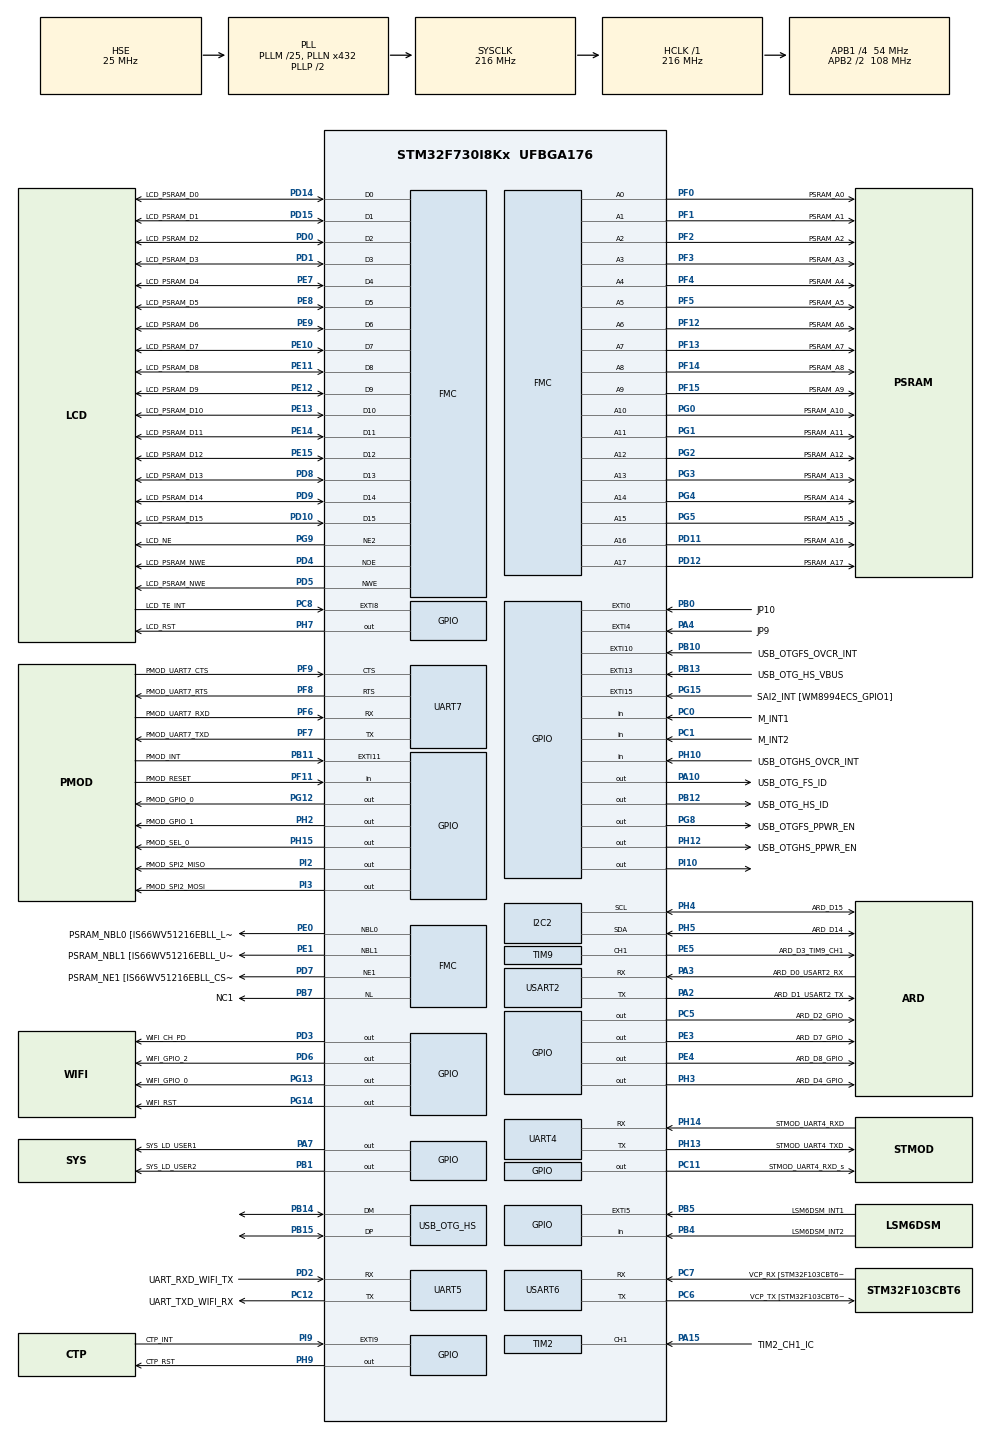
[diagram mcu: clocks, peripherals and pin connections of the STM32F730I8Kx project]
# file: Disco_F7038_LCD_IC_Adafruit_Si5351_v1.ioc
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FMC.WriteOperation1=FMC_WRITE_OPERATION_ENABLE
I2C2.Timing=0x20404768
Mcu.Family=STM32F7
Mcu.Name=STM32F730I8Kx
Mcu.Package=UFBGA176
NVIC.PriorityGroup=NVIC_PRIORITYGROUP_4
NVIC.TIM2_IRQn=true\:0\:0\:false\:false\:true\:true\:true
PA0-WKUP.GPIO_Label=SYS_B_User
PA0-WKUP.Mode=SYS_WakeUp0
PA0-WKUP.Signal=SYS_WKUP1
PA1.GPIO_Label=TIM2_PWM_CH2
PA1.Signal=S_TIM2_CH2
PA10.GPIO_Label=USB_OTG_FS_ID
PA10.Signal=GPIO_Output
PA11.Signal=USB_OTG_FS_DM
PA12.Signal=USB_OTG_FS_DP
PA13.Mode=Trace_Asynchronous_SW
PA13.Signal=SYS_JTMS-SWDIO
PA14.Mode=Trace_Asynchronous_SW
PA14.Signal=SYS_JTCK-SWCLK
PA15.GPIO_Label=TIM2_CH1_IC
PA15.Signal=S_TIM2_CH1_ETR
PA2.GPIO_Label=ARD_D1_USART2_TX
PA2.Mode=Asynchronous
PA2.Signal=USART2_TX
PA3.GPIO_Label=ARD_D0_USART2_RX
PA3.Mode=Asynchronous
PA3.Signal=USART2_RX
PA4.GPIO_Label=JP9
PA4.Signal=GPXTI4
PA5.GPIO_Label=ARD_D13_SPI1_SCK
PA5.Signal=SPI1_SCK
PA6.GPIO_Label=ARD_A0
PA6.Signal=ADCx_IN6
PA7.GPIO_Label=SYS_LD_USER1
PA7.Signal=GPIO_Output
PA8.GPIO_Label=CTP_SCL
PA8.Signal=I2C3_SCL
PA9.Signal=USB_OTG_FS_VBUS
PB0.GPIO_Label=JP10
PB0.Signal=GPXTI0
PB1.GPIO_Label=SYS_LD_USER2
PB1.Signal=GPIO_Output
PB10.GPIO_Label=USB_OTGFS_OVCR_INT
PB10.Signal=GPXTI10
PB11.GPIO_Label=PMOD_INT
PB11.Signal=GPXTI11
PB12.GPIO_Label=USB_OTG_HS_ID
PB12.Signal=GPIO_Output
PB13.GPIO_Label=USB_OTG_HS_VBUS
PB13.Signal=GPXTI13
PB14.Mode=Internal_Phy_Host
PB14.Signal=USB_OTG_HS_DM
PB15.Mode=Internal_Phy_Host
PB15.Signal=USB_OTG_HS_DP
PB2.GPIO_Label=QSPI_CLK [MX25L51245G_SCLK]
PB2.Signal=QUADSPI_CLK
PB3.GPIO_Label=SYS_STLINK_JTDO_SWO
PB3.Mode=Trace_Asynchronous_SW
PB3.Signal=SYS_JTDO-SWO
PB4.GPIO_Label=LSM6DSM_INT2
PB4.Signal=GPIO_Input
PB5.GPIO_Label=LSM6DSM_INT1
PB5.Signal=GPXTI5
PB6.GPIO_Label=QSPI_NCS [MX25L51245G_CS]
PB6.Signal=QUADSPI_BK1_NCS
PB7.GPIO_Label=NC1
PB7.Signal=FMC_NL
PC0.GPIO_Label=M_INT1
PC0.Signal=GPIO_Input
PC1.GPIO_Label=M_INT2
PC1.Signal=GPIO_Input
PC10.GPIO_Label=QSPI_D1 [MX25L51245G_SIO1]
PC10.Signal=QUADSPI_BK1_IO1
PC11.GPIO_Label=STMOD_UART4_RXD_s
PC11.Signal=GPIO_Output
PC12.GPIO_Label=UART_TXD_WIFI_RX
PC12.Mode=Asynchronous
PC12.Signal=UART5_TX
PC14-OSC32_IN.Mode=LSE-External-Oscillator
PC14-OSC32_IN.Signal=RCC_OSC32_IN
PC15-OSC32_OUT.Mode=LSE-External-Oscillator
PC15-OSC32_OUT.Signal=RCC_OSC32_OUT
PC2.GPIO_Label=STMOD_SPI2_MISOs
PC2.Signal=SPI2_MISO
PC3.GPIO_Label=STMOD+_SPI2_MOSIs
PC3.Signal=SPI2_MOSI
PC4.GPIO_Label=ARD_A2
PC4.Signal=ADCx_IN14
PC5.GPIO_Label=ARD_D2_GPIO
PC5.Signal=GPIO_Output
PC6.GPIO_Label=VCP_TX [STM32F103CBT6_PA3]
PC6.Mode=Asynchronous
PC6.Signal=USART6_TX
PC7.GPIO_Label=VCP_RX [STM32F103CBT6_PA2]
PC7.Mode=Asynchronous
PC7.Signal=USART6_RX
PC8.GPIO_Label=LCD_TE_INT
PC8.Signal=GPXTI8
PC9.GPIO_Label=QSPI_D0 [MX25L51245G_SIO0]
PC9.Signal=QUADSPI_BK1_IO0
PD0.GPIO_Label=LCD_PSRAM_D2
PD0.Signal=FMC_D2_DA2
PD1.GPIO_Label=LCD_PSRAM_D3
PD1.Signal=FMC_D3_DA3
PD10.GPIO_Label=LCD_PSRAM_D15
PD10.Signal=FMC_D15_DA15
PD11.GPIO_Label=PSRAM_A16
PD11.Signal=FMC_A16_CLE
PD12.GPIO_Label=PSRAM_A17
PD12.Signal=FMC_A17_ALE
PD13.GPIO_Label=QSPI_D3 [MX25L51245G_SIO3]
PD13.Signal=QUADSPI_BK1_IO3
PD14.GPIO_Label=LCD_PSRAM_D0
PD14.Signal=FMC_D0_DA0
PD15.GPIO_Label=LCD_PSRAM_D1
PD15.Signal=FMC_D1_DA1
PD2.GPIO_Label=UART_RXD_WIFI_TX
PD2.Mode=Asynchronous
PD2.Signal=UART5_RX
PD3.GPIO_Label=WIFI_CH_PD
PD3.Signal=GPIO_Output
PD4.GPIO_Label=LCD_PSRAM_NWE
PD4.Signal=FMC_NOE
PD5.GPIO_Label=LCD_PSRAM_NWE
PD5.Signal=FMC_NWE
PD6.GPIO_Label=WIFI_GPIO_2
PD6.Signal=GPIO_Output
PD7.GPIO_Label=PSRAM_NE1 [IS66WV51216EBLL_CS1]
PD7.Mode=NorPsramChipSelect1_1
PD7.Signal=FMC_NE1
PD8.GPIO_Label=LCD_PSRAM_D13
PD8.Signal=FMC_D13_DA13
PD9.GPIO_Label=LCD_PSRAM_D14
PD9.Signal=FMC_D14_DA14
PE0.GPIO_Label=PSRAM_NBL0 [IS66WV51216EBLL_LB]
PE0.Signal=FMC_NBL0
PE1.GPIO_Label=PSRAM_NBL1 [IS66WV51216EBLL_UB]
PE1.Signal=FMC_NBL1
PE10.GPIO_Label=LCD_PSRAM_D7
PE10.Signal=FMC_D7_DA7
PE11.GPIO_Label=LCD_PSRAM_D8
PE11.Signal=FMC_D8_DA8
PE12.GPIO_Label=LCD_PSRAM_D9
PE12.Signal=FMC_D9_DA9
PE13.GPIO_Label=LCD_PSRAM_D10
PE13.Signal=FMC_D10_DA10
PE14.GPIO_Label=LCD_PSRAM_D11
PE14.Signal=FMC_D11_DA11
PE15.GPIO_Label=LCD_PSRAM_D12
PE15.Signal=FMC_D12_DA12
PE2.GPIO_Label=QSPI_D2 [MX25L51245G_SIO2]
PE2.Signal=QUADSPI_BK1_IO2
PE3.GPIO_Label=ARD_D7_GPIO
PE3.Signal=GPIO_Output
PE4.GPIO_Label=ARD_D8_GPIO
PE4.Signal=GPIO_Output
PE5.GPIO_Label=ARD_D3_TIM9_CH1
PE5.Signal=S_TIM9_CH1
PE6.GPIO_Label=ARD_D6_TIM9_CH2
PE6.Signal=S_TIM9_CH2
PE7.GPIO_Label=LCD_PSRAM_D4
PE7.Signal=FMC_D4_DA4
PE8.GPIO_Label=LCD_PSRAM_D5
PE8.Signal=FMC_D5_DA5
PE9.GPIO_Label=LCD_PSRAM_D6
PE9.Signal=FMC_D6_DA6
PF0.GPIO_Label=PSRAM_A0
PF0.Signal=FMC_A0
PF1.GPIO_Label=PSRAM_A1
PF1.Signal=FMC_A1
PF10.GPIO_Label=ARD_A3_ADC3_IN8
PF10.Signal=ADC3_IN8
PF11.GPIO_Label=PMOD_RESET
PF11.Signal=GPIO_Input
PF12.GPIO_Label=PSRAM_A6
PF12.Signal=FMC_A6
PF13.GPIO_Label=PSRAM_A7
PF13.Signal=FMC_A7
PF14.GPIO_Label=PSRAM_A8
PF14.Signal=FMC_A8
PF15.GPIO_Label=PSRAM_A9
PF15.Signal=FMC_A9
PF2.GPIO_Label=PSRAM_A2
PF2.Signal=FMC_A2
PF3.GPIO_Label=PSRAM_A3
PF3.Signal=FMC_A3
PF4.GPIO_Label=PSRAM_A4
PF4.Signal=FMC_A4
PF5.GPIO_Label=PSRAM_A5
PF5.Signal=FMC_A5
PF6.GPIO_Label=PMOD_UART7_RXD
PF6.Mode=Asynchronous
PF6.Signal=UART7_RX
PF7.GPIO_Label=PMOD_UART7_TXD
PF7.Mode=Asynchronous
PF7.Signal=UART7_TX
PF8.GPIO_Label=PMOD_UART7_RTS
PF8.Mode=CTS_RTS
PF8.Signal=UART7_RTS
PF9.GPIO_Label=PMOD_UART7_CTS
PF9.Mode=CTS_RTS
PF9.Signal=UART7_CTS
PG0.GPIO_Label=PSRAM_A10
PG0.Signal=FMC_A10
PG1.GPIO_Label=PSRAM_A11
PG1.Signal=FMC_A11
PG10.GPIO_Label=SAI2_SD_B [SAI2_SD_B_ADCDAT1]
PG10.Signal=SAI2_SD_B
PG12.GPIO_Label=PMOD_GPIO_0
PG12.Signal=GPIO_Output
PG13.GPIO_Label=WIFI_GPIO_0
PG13.Signal=GPIO_Output
PG14.GPIO_Label=WIFI_RST
PG14.Signal=GPIO_Output
PG15.GPIO_Label=SAI2_INT [WM8994ECS_GPIO1]
PG15.Signal=GPXTI15
PG2.GPIO_Label=PSRAM_A12
PG2.Signal=FMC_A12
PG3.GPIO_Label=PSRAM_A13
PG3.Signal=FMC_A13
PG4.GPIO_Label=PSRAM_A14
PG4.Signal=FMC_A14_BA0
PG5.GPIO_Label=PSRAM_A15
PG5.Signal=FMC_A15_BA1
PG8.GPIO_Label=USB_OTGFS_PPWR_EN
PG8.Signal=GPIO_Output
PG9.GPIO_Label=LCD_NE
PG9.Mode=NorPsramChipSelect2_2
PG9.Signal=FMC_NE2
PH0-OSC_IN.Mode=HSE-External-Oscillator
PH0-OSC_IN.Signal=RCC_OSC_IN
PH1-OSC_OUT.Mode=HSE-External-Oscillator
PH1-OSC_OUT.Signal=RCC_OSC_OUT
PH10.GPIO_Label=USB_OTGHS_OVCR_INT
PH10.Signal=GPIO_Input
PH11.GPIO_Label=LCD_BL [STLD40DPUR_EN]
PH11.Signal=S_TIM5_CH2
PH12.GPIO_Label=USB_OTGHS_PPWR_EN
PH12.Signal=GPIO_Output
PH13.GPIO_Label=STMOD_UART4_TXD
PH13.Mode=Asynchronous
PH13.Signal=UART4_TX
PH14.GPIO_Label=STMOD_UART4_RXD
PH14.Mode=Asynchronous
PH14.Signal=UART4_RX
PH15.GPIO_Label=PMOD_SEL_0
PH15.PinState=GPIO_PIN_SET
PH15.Signal=GPIO_Output
PH2.GPIO_Label=PMOD_GPIO_1
PH2.Signal=GPIO_Output
PH3.GPIO_Label=ARD_D4_GPIO
PH3.Signal=GPIO_Output
PH4.GPIO_Label=ARD_D15
PH4.Mode=I2C
PH4.Signal=I2C2_SCL
PH5.GPIO_Label=ARD_D14
PH5.GPIO_Pu=GPIO_PULLUP
PH5.Mode=I2C
PH5.Signal=I2C2_SDA
PH6.GPIO_Label=ARD_D9_TIM12_CH1
PH6.Signal=S_TIM12_CH1
PH7.GPIO_Label=LCD_RST
PH7.Signal=GPIO_Output
PH8.GPIO_Label=CTP_SDA
PH8.Signal=I2C3_SDA
PH9.GPIO_Label=CTP_RST
PH9.Signal=GPIO_Output
PI0.GPIO_Label=PMOD_SPI2_NSS
PI0.Signal=SPI2_NSS
PI1.GPIO_Label=PMOD_SPI2_SCK
PI1.Signal=SPI2_SCK
PI10.Signal=GPIO_Output
PI2.GPIO_Label=PMOD_SPI2_MISO
PI2.Signal=GPIO_Output
PI3.GPIO_Label=PMOD_SPI2_MOSI
PI3.Signal=GPIO_Output
PI4.GPIO_Label=SAI2_MCLK_A [WM8994ECS_MCLK1]
PI4.Signal=SAI2_MCLK_A
PI5.GPIO_Label=SAI2_SCK_A [WM8994ECS_BCLK1]
PI5.Signal=SAI2_SCK_A
PI6.GPIO_Label=SAI2_SD_A [WM8994ECS_DACDAT1]
PI6.Signal=SAI2_SD_A
PI7.GPIO_Label=SAI2_FS_A [WM8994ECS_LRCLK1]
PI7.Signal=SAI2_FS_A
PI9.GPIO_Label=CTP_INT
PI9.Signal=GPXTI9
ProjectManager.HeapSize=0x200
ProjectManager.StackSize=0x400
ProjectManager.TargetToolchain=STM32CubeIDE
RCC.AHBFreq_Value=216000000
RCC.APB1CLKDivider=RCC_HCLK_DIV4
RCC.APB1Freq_Value=54000000
RCC.APB1TimFreq_Value=108000000
RCC.APB2CLKDivider=RCC_HCLK_DIV2
RCC.APB2Freq_Value=108000000
RCC.APB2TimFreq_Value=216000000
RCC.CortexFreq_Value=216000000
RCC.HCLKFreq_Value=216000000
RCC.HSE_VALUE=25000000
RCC.HSI_VALUE=16000000
RCC.PLLM=25
RCC.PLLN=432
RCC.PLLQ=9
RCC.PLLSourceVirtual=RCC_PLLSOURCE_HSE
RCC.SYSCLKFreq_VALUE=216000000
RCC.SYSCLKSource=RCC_SYSCLKSOURCE_PLLCLK
RCC.USBFreq_Value=48000000
RCC.VCOOutputFreq_Value=432000000
REXTPHYHS.GPIO_Label=REXT_OTGPHY
REXTPHYHS.Signal=USB_OTG_HS_REXTPHYHS
SH.ADCx_IN14.0=ADC2_IN14
SH.ADCx_IN14.1=ADC1_IN14
SH.ADCx_IN6.0=ADC2_IN6
SH.ADCx_IN6.1=ADC1_IN6
SH.FMC_A0.0=FMC_A0,18b-a1
SH.FMC_A0.1=FMC_A0,A0_2
SH.FMC_A1.0=FMC_A1,18b-a1
SH.FMC_A10.0=FMC_A10,18b-a1
SH.FMC_A11.0=FMC_A11,18b-a1
SH.FMC_A12.0=FMC_A12,18b-a1
SH.FMC_A13.0=FMC_A13,18b-a1
SH.FMC_A14_BA0.0=FMC_A14,18b-a1
SH.FMC_A15_BA1.0=FMC_A15,18b-a1
SH.FMC_A16_CLE.0=FMC_A16,18b-a1
SH.FMC_A17_ALE.0=FMC_A17,18b-a1
SH.FMC_A2.0=FMC_A2,18b-a1
SH.FMC_A3.0=FMC_A3,18b-a1
SH.FMC_A4.0=FMC_A4,18b-a1
SH.FMC_A5.0=FMC_A5,18b-a1
SH.FMC_A6.0=FMC_A6,18b-a1
SH.FMC_A7.0=FMC_A7,18b-a1
SH.FMC_A8.0=FMC_A8,18b-a1
SH.FMC_A9.0=FMC_A9,18b-a1
SH.FMC_D0_DA0.0=FMC_D0,16b-d1
SH.FMC_D0_DA0.1=FMC_D0,16b-d2
SH.FMC_D10_DA10.0=FMC_D10,16b-d1
SH.FMC_D10_DA10.1=FMC_D10,16b-d2
SH.FMC_D11_DA11.0=FMC_D11,16b-d1
SH.FMC_D11_DA11.1=FMC_D11,16b-d2
SH.FMC_D12_DA12.0=FMC_D12,16b-d1
SH.FMC_D12_DA12.1=FMC_D12,16b-d2
SH.FMC_D13_DA13.0=FMC_D13,16b-d1
SH.FMC_D13_DA13.1=FMC_D13,16b-d2
SH.FMC_D14_DA14.0=FMC_D14,16b-d1
SH.FMC_D14_DA14.1=FMC_D14,16b-d2
SH.FMC_D15_DA15.0=FMC_D15,16b-d1
SH.FMC_D15_DA15.1=FMC_D15,16b-d2
SH.FMC_D1_DA1.0=FMC_D1,16b-d1
SH.FMC_D1_DA1.1=FMC_D1,16b-d2
SH.FMC_D2_DA2.0=FMC_D2,16b-d1
SH.FMC_D2_DA2.1=FMC_D2,16b-d2
SH.FMC_D3_DA3.0=FMC_D3,16b-d1
SH.FMC_D3_DA3.1=FMC_D3,16b-d2
SH.FMC_D4_DA4.0=FMC_D4,16b-d1
SH.FMC_D4_DA4.1=FMC_D4,16b-d2
SH.FMC_D5_DA5.0=FMC_D5,16b-d1
SH.FMC_D5_DA5.1=FMC_D5,16b-d2
SH.FMC_D6_DA6.0=FMC_D6,16b-d1
SH.FMC_D6_DA6.1=FMC_D6,16b-d2
SH.FMC_D7_DA7.0=FMC_D7,16b-d1
SH.FMC_D7_DA7.1=FMC_D7,16b-d2
SH.FMC_D8_DA8.0=FMC_D8,16b-d1
SH.FMC_D8_DA8.1=FMC_D8,16b-d2
SH.FMC_D9_DA9.0=FMC_D9,16b-d1
SH.FMC_D9_DA9.1=FMC_D9,16b-d2
SH.FMC_NBL0.0=FMC_NBL0,2ByteEnable1
SH.FMC_NBL1.0=FMC_NBL1,2ByteEnable1
SH.FMC_NL.0=FMC_NL,AddressValid1
SH.FMC_NOE.0=FMC_NOE,Psram1
SH.FMC_NOE.1=FMC_NOE,Lcd2
SH.FMC_NWE.0=FMC_NWE,Psram1
SH.FMC_NWE.1=FMC_NWE,Lcd2
SH.S_TIM12_CH1.0=TIM12_CH1
SH.S_TIM2_CH1_ETR.0=TIM2_CH1,Input_Capture1_from_TI1
SH.S_TIM2_CH2.0=TIM2_CH2
SH.S_TIM5_CH2.0=TIM5_CH2
SH.S_TIM9_CH1.0=TIM9_CH1,PWM Generation1 CH1
SH.S_TIM9_CH2.0=TIM9_CH2
TIM2.Channel-Input_Capture1_from_TI1=TIM_CHANNEL_1
TIM2.Period=0xffffffff
TIM9.Channel-PWM\ Generation1\ CH1=TIM_CHANNEL_1
TIM9.Period=49999
TIM9.Prescaler=215
TIM9.Pulse-PWM\ Generation1\ CH1=24999
USART2.VirtualMode-Asynchronous=VM_ASYNC
USART6.VirtualMode-Asynchronous=VM_ASYNC
VP_TIM2_VS_ClockSourceINT.Mode=Internal
VP_TIM9_VS_ClockSourceINT.Mode=Internal
board=STM32F7308-DK

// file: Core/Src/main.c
/* USER CODE BEGIN Header */
/**
 ******************************************************************************
 * @file           : main.c
 * @brief          : Main program body
 ******************************************************************************
 * @attention
 *
 * <h2><center>&copy; Copyright (c) 2020 STMicroelectronics.
 * All rights reserved.</center></h2>
 *
 * This software component is licensed by ST under Ultimate Liberty license
 * SLA0044, the "License"; You may not use this file except in compliance with
 * the License. You may obtain a copy of the License at:
 *                             www.st.com/SLA0044
 *
 ******************************************************************************
 */
/** MANDATORY
select the minimum number of peripherals to avoid overflow of the flash memory
 */
/* USER CODE END Header */
#include "main.h"

/* USER CODE BEGIN Includes */
#include <stdio.h>
#include <math.h>
#include <string.h> /* strlen */
#include <inttypes.h>
#include "si5351.h"

/* USER CODE END Includes */

/* USER CODE BEGIN PTD */

#define TX_BUF_DIM    1000
#define BOOT_TIME   	15 //ms
/* USER CODE END PTD */

/* USER CODE BEGIN PD */
/* Private define ------------------------------------------------------------*/
#define LCD_FEATURES_NUM                5
#define HEADBAND_HEIGHT                 64

/* USER CODE END PD */

I2C_HandleTypeDef hi2c2;

TIM_HandleTypeDef htim2;
TIM_HandleTypeDef htim9;

UART_HandleTypeDef huart4;
UART_HandleTypeDef huart5;
UART_HandleTypeDef huart7;
UART_HandleTypeDef huart2;
UART_HandleTypeDef huart6;

SRAM_HandleTypeDef hsram1;
SRAM_HandleTypeDef hsram2;

/* USER CODE BEGIN PV */
/* Private variables ---------------------------------------------------------*/
#define i2c_handle hi2c2

uint32_t captures[2];
volatile uint8_t  captureDone = 0;
volatile uint16_t uhCaptureIndex = 0;
volatile uint32_t diffCapture = 0;
volatile float period = 0;

#define BUF_SIZE 128
char buffer[BUF_SIZE];
/* USER CODE END PV */

void SystemClock_Config(void);
static void MX_GPIO_Init(void);
static void MX_FMC_Init(void);
static void MX_TIM2_Init(void);
static void MX_TIM9_Init(void);
static void MX_UART4_Init(void);
static void MX_UART5_Init(void);
static void MX_UART7_Init(void);
static void MX_USART2_UART_Init(void);
static void MX_USART6_UART_Init(void);
static void MX_I2C2_Init(void);
/* USER CODE BEGIN PFP */
static void MX_GPIO_Init(void);
void Error_Callback(void);
void lsm6dsl_read_data_polling(void);

static float getFrequency(void);
/* USER CODE END PFP */

/* USER CODE BEGIN 0 */
uint32_t DWT_Delay_Init(void)
{
	/* Disable TRC */
	CoreDebug->DEMCR &= ~CoreDebug_DEMCR_TRCENA_Msk; // ~0x01000000;
	/* Enable TRC */
	CoreDebug->DEMCR |=  CoreDebug_DEMCR_TRCENA_Msk; // 0x01000000;
	/* Disable clock cycle counter */
	DWT->CTRL &= ~DWT_CTRL_CYCCNTENA_Msk; //~0x00000001;
	/* Enable  clock cycle counter */
	DWT->CTRL |=  DWT_CTRL_CYCCNTENA_Msk; //0x00000001;
	/* Reset the clock cycle counter value */
	DWT->CYCCNT = 0;
	/* 3 NO OPERATION instructions */
	__ASM volatile ("NOP");
	__ASM volatile ("NOP");
	__ASM volatile ("NOP");
	/* Check if clock cycle counter has started */
	if(DWT->CYCCNT)
	{
		return 0; /*clock cycle counter started*/
	}
	else
	{
		return 1; /*clock cycle counter not started*/
	}
}

// This Function Provides Delay In Microseconds Using DWT
__STATIC_INLINE void DWT_Delay_us(volatile uint32_t au32_microseconds)
{
	uint32_t au32_initial_ticks = DWT->CYCCNT;
	uint32_t au32_ticks = (HAL_RCC_GetHCLKFreq() / 1000000);
	au32_microseconds *= au32_ticks;
	while ((DWT->CYCCNT - au32_initial_ticks) < au32_microseconds-au32_ticks);
}

/**
 * @brief  Configure the MPU attributes as Write Back for PSRAM mapped on FMC
 *         BANK1/BANK2. This function configures two regions.
 * @note   The Base Address is 0x64000000 (for Display purposes) and
 *         0x60000000 (for Audio Record module).
 *         The Region Size is 512KB, it is related to PSRAM memory size.
 * @param  None
 * @retval None
 */
static void MPU_ConfigPSRAM(void)
{
	MPU_Region_InitTypeDef MPU_InitStruct;

	/* Disable the MPU */
	HAL_MPU_Disable();

	/* Configure the MPU attributes for PSRAM with recomended configurations:
     Normal memory, Shareable, write-back (Display purposes) */
	MPU_InitStruct.Enable = MPU_REGION_ENABLE;
	MPU_InitStruct.BaseAddress = 0x64000000;
	MPU_InitStruct.Size = MPU_REGION_SIZE_512KB;
	MPU_InitStruct.AccessPermission = MPU_REGION_FULL_ACCESS;
	MPU_InitStruct.IsBufferable = MPU_ACCESS_BUFFERABLE;
	MPU_InitStruct.IsCacheable = MPU_ACCESS_CACHEABLE;
	MPU_InitStruct.IsShareable = MPU_ACCESS_SHAREABLE;
	MPU_InitStruct.Number = MPU_REGION_NUMBER0;
	MPU_InitStruct.TypeExtField = MPU_TEX_LEVEL0;
	MPU_InitStruct.SubRegionDisable = 0x00;
	MPU_InitStruct.DisableExec = MPU_INSTRUCTION_ACCESS_ENABLE;

	HAL_MPU_ConfigRegion(&MPU_InitStruct);

	/* Configure the MPU attributes for PSRAM with recomended configurations:
     Normal memory, Shareable, write-back */
	MPU_InitStruct.BaseAddress = 0x60000000;
	MPU_InitStruct.Number = MPU_REGION_NUMBER1;

	HAL_MPU_ConfigRegion(&MPU_InitStruct);

	/* Enable the MPU */
	HAL_MPU_Enable(MPU_PRIVILEGED_DEFAULT);
}

/**
 * @brief  CPU L1-Cache enable.
 * @param  None
 * @retval None
 */
static void CPU_CACHE_Enable(void)
{
	/* Enable I-Cache */
	SCB_EnableICache();

	/* Enable D-Cache */
	SCB_EnableDCache();
}

/*
 *  Function to print messages
 */
// WARNING UART6 is connected to st-link
static void tx_com( uint8_t *tx_buffer, uint16_t len )
{
#ifdef NUCLEO_STM32F411RE
	HAL_UART_Transmit( &huart2, tx_buffer, len, 1000 );
#endif
#ifdef USE_STM32F7308_DISCO
	HAL_UART_Transmit( &huart6, tx_buffer, len, 1000 );
	HAL_Delay(1000);
#endif
#ifdef MKI109V2
	CDC_Transmit_FS( tx_buffer, len );
#endif
}

// WARNING UART6 is connected to st-link
// Properties -> Settings -> MCU_Settings -> select use float with printf
/*
 * USART1, BaudRate = 115200, WordLength = UART_WORDLENGTH_8B, StopBits = UART_STOPBITS_1;
 * */
int _write(int file, char *ptr, int len)
{
	HAL_UART_Transmit(&huart6,(uint8_t *)ptr, len, 10);
	return len;
}

/* USER CODE END 0 */

int main(void)
{
	/* USER CODE BEGIN 1 */
	uint8_t  lcd_status = LCD_ERROR;

	/* Configure the MPU attributes for PSRAM external memory */
	MPU_ConfigPSRAM();

	/* Enable the CPU Cache */
	CPU_CACHE_Enable();

	/* USER CODE END 1 */

	/* MCU Configuration--------------------------------------------------------*/

	/* Reset of all peripherals, Initializes the Flash interface and the Systick. */
	HAL_Init();

	/* Configure the system clock */
	SystemClock_Config();

	/* Initialize all configured peripherals */
	MX_GPIO_Init();
	MX_FMC_Init();
	MX_TIM2_Init();
	MX_TIM9_Init();
	MX_UART4_Init();
	MX_UART5_Init();
	MX_UART7_Init();
	MX_USART2_UART_Init();
	MX_USART6_UART_Init();
	MX_I2C2_Init();
	/* USER CODE BEGIN 2 */

	DWT_Delay_Init();

	Si5351_ConfigTypeDef Si5351_ConfigStruct;

	/* Initialize the LCD */
	lcd_status = BSP_LCD_Init();
	if (lcd_status != LCD_OK)
	   Error_Handler();

	BSP_LCD_SetFont(&LCD_DEFAULT_FONT);

	/* Clear the LCD */
	BSP_LCD_SetBackColor(LCD_COLOR_WHITE);
	BSP_LCD_Clear(LCD_COLOR_WHITE);

	/* Set the LCD Text Color */
	BSP_LCD_SetTextColor(LCD_COLOR_DARKBLUE);

	/* Display LCD messages */
	BSP_LCD_DisplayStringAt(0,  2, (uint8_t *)"STM32F7308 BSP",   CENTER_MODE);
	BSP_LCD_DisplayStringAt(0, 14, (uint8_t *)"Drivers examples", CENTER_MODE);

	/*
typedef struct
{
	Si5351_MSClockSourceTypeDef MS_Clock_Source; //select source on MS input
	uint32_t MS_Divider_Integer;		//the integer part of divider, called "a"
	uint32_t MS_Divider_Numerator;		//the numerator, called "b"
	uint32_t MS_Divider_Denominator;	//the denominator, called "c"
} Si5351_MSConfigTypeDef;	//sets MS divider ( a+(b/c) ) and clock (PLLA/PLLB)

	 */
	Si5351_StructInit(&Si5351_ConfigStruct);	//initialize the structure with default "safe" values
	Si5351_ConfigStruct.OSC.OSC_XTAL_Load = XTAL_Load_8_pF;	//use 8 pF load for crystal

	Si5351_ConfigStruct.PLL[0].PLL_Clock_Source = PLL_Clock_Source_XTAL;	//select xrystal as clock input for the PLL
	Si5351_ConfigStruct.PLL[0].PLL_Multiplier_Integer = 32;	//multiply the clock frequency by 32, this gets us 800 MHz clock

	Si5351_ConfigStruct.MS[0].MS_Clock_Source = MS_Clock_Source_PLLA;	//select PLLA as clock source for MultiSynth 0
	Si5351_ConfigStruct.MS[0].MS_Divider_Integer = 250;	//divide the 800 MHz by 250 this gets us 3.2 MHz

	Si5351_ConfigStruct.CLK[0].CLK_R_Div = CLK_R_Div8;	//divide the MultiSynth output by 64, this gets us 500 kHz
	Si5351_ConfigStruct.CLK[0].CLK_Enable = ON;	//turn on the output

	Si5351_ConfigStruct.MS[1].MS_Clock_Source = MS_Clock_Source_PLLA;	//select PLLA as clock source for MultiSynth 1
	Si5351_ConfigStruct.MS[1].MS_Divider_Integer = 250;	//divide the 800 MHz by 250 this gets us 1.6 MHz

	Si5351_ConfigStruct.CLK[1].CLK_R_Div = CLK_R_Div8;	//divide the MultiSynth output by 64, this gets us 25 kHz
	Si5351_ConfigStruct.CLK[1].CLK_Enable = ON;	//turn on the output

	Si5351_Init(&Si5351_ConfigStruct);	//apply the changes

	printf("start\n");
	// TIM1_freq =108 MHz
	// T = (ARR+1)*(PSC+1)/108e6=0.1  avec PSC=215 ARR=49999
	// Pulse=24999 => freq = 20 Hz
	// T = (ARR+1)*(PSC+1)/108e6=3.185185185185185e-06  avec PSC=42 ARR=7
	// Pulse=3  => freq = 627906.97 Hz

	if ( HAL_OK != HAL_TIM_PWM_Start (&htim9, TIM_CHANNEL_1) )
		Error_Handler();

	// Start the Input Capture in interrupt mode
	if (HAL_OK != HAL_TIM_IC_Start_IT(&htim2, TIM_CHANNEL_1) )
		Error_Handler();

	uint32_t count0=250;
	uint32_t count =count0;
	/* USER CODE END 2 */

	/* Infinite loop */
	while (1)
	{

		/* USER CODE BEGIN 3 */

		//#define DEVINFO
#ifdef DEVINFO
		uint32_t CCR_value = __HAL_TIM_GetCompare(&htim9, TIM_CHANNEL_1);
		uint32_t TIM9_count = __HAL_TIM_GetCounter(&htim9);
		GPIO_PinState PE5_state=HAL_GPIO_ReadPin (GPIOE, GPIO_PIN_5);
		printf("CCR_value %lu count %lu PE5_state %d\n", CCR_value, TIM1_count, PE5_state);
#endif

		//__disable_irq();
		Si5351_ConfigStruct.MS[1].MS_Divider_Integer = count;	//divide the 800 MHz by 250 this gets us 1.6 MHz
		Si5351_Init(&Si5351_ConfigStruct);	//apply the changes
		//__enable_irq();
		//HAL_Delay(1);
		DWT_Delay_us(10);

#define CAPTURE
#ifdef CAPTURE
		float freq=getFrequency();
		float fth = 25e6*32./8./count;
		printf("freq %f Hz %f Hz relative err %f\n", freq, fth, fabs(1.0-freq/fth));
#endif

		count++;
		if (count>2040) count=count0;

	}
	/* USER CODE END 3 */
}

void SystemClock_Config(void)
{
	RCC_OscInitTypeDef RCC_OscInitStruct = {0};
	RCC_ClkInitTypeDef RCC_ClkInitStruct = {0};
	RCC_PeriphCLKInitTypeDef PeriphClkInitStruct = {0};

	/** Configure LSE Drive Capability
	 */
	HAL_PWR_EnableBkUpAccess();
	/** Configure the main internal regulator output voltage
	 */
	__HAL_RCC_PWR_CLK_ENABLE();
	__HAL_PWR_VOLTAGESCALING_CONFIG(PWR_REGULATOR_VOLTAGE_SCALE1);
	/** Initializes the RCC Oscillators according to the specified parameters
	 * in the RCC_OscInitTypeDef structure.
	 */
	RCC_OscInitStruct.OscillatorType = RCC_OSCILLATORTYPE_HSE;
	RCC_OscInitStruct.HSEState = RCC_HSE_ON;
	RCC_OscInitStruct.PLL.PLLState = RCC_PLL_ON;
	RCC_OscInitStruct.PLL.PLLSource = RCC_PLLSOURCE_HSE;
	RCC_OscInitStruct.PLL.PLLM = 25;
	RCC_OscInitStruct.PLL.PLLN = 432;
	RCC_OscInitStruct.PLL.PLLP = RCC_PLLP_DIV2;
	RCC_OscInitStruct.PLL.PLLQ = 9;
	if (HAL_RCC_OscConfig(&RCC_OscInitStruct) != HAL_OK)
	{
		Error_Handler();
	}
	/** Activate the Over-Drive mode
	 */
	if (HAL_PWREx_EnableOverDrive() != HAL_OK)
	{
		Error_Handler();
	}
	/** Initializes the CPU, AHB and APB buses clocks
	 */
	RCC_ClkInitStruct.ClockType = RCC_CLOCKTYPE_HCLK|RCC_CLOCKTYPE_SYSCLK
			|RCC_CLOCKTYPE_PCLK1|RCC_CLOCKTYPE_PCLK2;
	RCC_ClkInitStruct.SYSCLKSource = RCC_SYSCLKSOURCE_PLLCLK;
	RCC_ClkInitStruct.AHBCLKDivider = RCC_SYSCLK_DIV1;
	RCC_ClkInitStruct.APB1CLKDivider = RCC_HCLK_DIV4;
	RCC_ClkInitStruct.APB2CLKDivider = RCC_HCLK_DIV2;

	if (HAL_RCC_ClockConfig(&RCC_ClkInitStruct, FLASH_LATENCY_7) != HAL_OK)
	{
		Error_Handler();
	}
	PeriphClkInitStruct.PeriphClockSelection = RCC_PERIPHCLK_USART2|RCC_PERIPHCLK_USART6
			|RCC_PERIPHCLK_UART4|RCC_PERIPHCLK_UART5
			|RCC_PERIPHCLK_UART7|RCC_PERIPHCLK_I2C2;
	PeriphClkInitStruct.Usart2ClockSelection = RCC_USART2CLKSOURCE_PCLK1;
	PeriphClkInitStruct.Uart4ClockSelection = RCC_UART4CLKSOURCE_PCLK1;
	PeriphClkInitStruct.Uart5ClockSelection = RCC_UART5CLKSOURCE_PCLK1;
	PeriphClkInitStruct.Usart6ClockSelection = RCC_USART6CLKSOURCE_PCLK2;
	PeriphClkInitStruct.Uart7ClockSelection = RCC_UART7CLKSOURCE_PCLK1;
	PeriphClkInitStruct.I2c2ClockSelection = RCC_I2C2CLKSOURCE_PCLK1;
	if (HAL_RCCEx_PeriphCLKConfig(&PeriphClkInitStruct) != HAL_OK)
	{
		Error_Handler();
	}
}

static void MX_I2C2_Init(void)
{

	hi2c2.Instance = I2C2;
	hi2c2.Init.Timing = 0x20404768;
	hi2c2.Init.OwnAddress1 = 0;
	hi2c2.Init.AddressingMode = I2C_ADDRESSINGMODE_7BIT;
	hi2c2.Init.DualAddressMode = I2C_DUALADDRESS_DISABLE;
	hi2c2.Init.OwnAddress2 = 0;
	hi2c2.Init.OwnAddress2Masks = I2C_OA2_NOMASK;
	hi2c2.Init.GeneralCallMode = I2C_GENERALCALL_DISABLE;
	hi2c2.Init.NoStretchMode = I2C_NOSTRETCH_DISABLE;
	if (HAL_I2C_Init(&hi2c2) != HAL_OK)
	{
		Error_Handler();
	}
	/** Configure Analogue filter
	 */
	if (HAL_I2CEx_ConfigAnalogFilter(&hi2c2, I2C_ANALOGFILTER_ENABLE) != HAL_OK)
	{
		Error_Handler();
	}
	/** Configure Digital filter
	 */
	if (HAL_I2CEx_ConfigDigitalFilter(&hi2c2, 0) != HAL_OK)
	{
		Error_Handler();
	}

}

static void MX_TIM2_Init(void)
{

	TIM_ClockConfigTypeDef sClockSourceConfig = {0};
	TIM_MasterConfigTypeDef sMasterConfig = {0};
	TIM_IC_InitTypeDef sConfigIC = {0};

	htim2.Instance = TIM2;
	htim2.Init.Prescaler = 0;
	htim2.Init.CounterMode = TIM_COUNTERMODE_UP;
	htim2.Init.Period = 0xffffffff;
	htim2.Init.ClockDivision = TIM_CLOCKDIVISION_DIV1;
	htim2.Init.AutoReloadPreload = TIM_AUTORELOAD_PRELOAD_DISABLE;
	if (HAL_TIM_Base_Init(&htim2) != HAL_OK)
	{
		Error_Handler();
	}
	sClockSourceConfig.ClockSource = TIM_CLOCKSOURCE_INTERNAL;
	if (HAL_TIM_ConfigClockSource(&htim2, &sClockSourceConfig) != HAL_OK)
	{
		Error_Handler();
	}
	if (HAL_TIM_IC_Init(&htim2) != HAL_OK)
	{
		Error_Handler();
	}
	sMasterConfig.MasterOutputTrigger = TIM_TRGO_RESET;
	sMasterConfig.MasterSlaveMode = TIM_MASTERSLAVEMODE_DISABLE;
	if (HAL_TIMEx_MasterConfigSynchronization(&htim2, &sMasterConfig) != HAL_OK)
	{
		Error_Handler();
	}
	sConfigIC.ICPolarity = TIM_INPUTCHANNELPOLARITY_RISING;
	sConfigIC.ICSelection = TIM_ICSELECTION_DIRECTTI;
	sConfigIC.ICPrescaler = TIM_ICPSC_DIV1;
	sConfigIC.ICFilter = 0;
	if (HAL_TIM_IC_ConfigChannel(&htim2, &sConfigIC, TIM_CHANNEL_1) != HAL_OK)
	{
		Error_Handler();
	}

}

static void MX_TIM9_Init(void)
{

	TIM_ClockConfigTypeDef sClockSourceConfig = {0};
	TIM_OC_InitTypeDef sConfigOC = {0};

	htim9.Instance = TIM9;
	htim9.Init.Prescaler = 215;
	htim9.Init.CounterMode = TIM_COUNTERMODE_UP;
	htim9.Init.Period = 49999;
	htim9.Init.ClockDivision = TIM_CLOCKDIVISION_DIV1;
	htim9.Init.AutoReloadPreload = TIM_AUTORELOAD_PRELOAD_DISABLE;
	if (HAL_TIM_Base_Init(&htim9) != HAL_OK)
	{
		Error_Handler();
	}
	sClockSourceConfig.ClockSource = TIM_CLOCKSOURCE_INTERNAL;
	if (HAL_TIM_ConfigClockSource(&htim9, &sClockSourceConfig) != HAL_OK)
	{
		Error_Handler();
	}
	if (HAL_TIM_PWM_Init(&htim9) != HAL_OK)
	{
		Error_Handler();
	}
	sConfigOC.OCMode = TIM_OCMODE_PWM1;
	sConfigOC.Pulse = 24999;
	sConfigOC.OCPolarity = TIM_OCPOLARITY_HIGH;
	sConfigOC.OCFastMode = TIM_OCFAST_DISABLE;
	if (HAL_TIM_PWM_ConfigChannel(&htim9, &sConfigOC, TIM_CHANNEL_1) != HAL_OK)
	{
		Error_Handler();
	}
	HAL_TIM_MspPostInit(&htim9);

}

static void MX_UART4_Init(void)
{

	huart4.Instance = UART4;
	huart4.Init.BaudRate = 115200;
	huart4.Init.WordLength = UART_WORDLENGTH_8B;
	huart4.Init.StopBits = UART_STOPBITS_1;
	huart4.Init.Parity = UART_PARITY_NONE;
	huart4.Init.Mode = UART_MODE_TX_RX;
	huart4.Init.HwFlowCtl = UART_HWCONTROL_NONE;
	huart4.Init.OverSampling = UART_OVERSAMPLING_16;
	huart4.Init.OneBitSampling = UART_ONE_BIT_SAMPLE_DISABLE;
	huart4.AdvancedInit.AdvFeatureInit = UART_ADVFEATURE_NO_INIT;
	if (HAL_UART_Init(&huart4) != HAL_OK)
	{
		Error_Handler();
	}

}

static void MX_UART5_Init(void)
{

	huart5.Instance = UART5;
	huart5.Init.BaudRate = 115200;
	huart5.Init.WordLength = UART_WORDLENGTH_8B;
	huart5.Init.StopBits = UART_STOPBITS_1;
	huart5.Init.Parity = UART_PARITY_NONE;
	huart5.Init.Mode = UART_MODE_TX_RX;
	huart5.Init.HwFlowCtl = UART_HWCONTROL_NONE;
	huart5.Init.OverSampling = UART_OVERSAMPLING_16;
	huart5.Init.OneBitSampling = UART_ONE_BIT_SAMPLE_DISABLE;
	huart5.AdvancedInit.AdvFeatureInit = UART_ADVFEATURE_NO_INIT;
	if (HAL_UART_Init(&huart5) != HAL_OK)
	{
		Error_Handler();
	}

}

static void MX_UART7_Init(void)
{

	huart7.Instance = UART7;
	huart7.Init.BaudRate = 115200;
	huart7.Init.WordLength = UART_WORDLENGTH_8B;
	huart7.Init.StopBits = UART_STOPBITS_1;
	huart7.Init.Parity = UART_PARITY_NONE;
	huart7.Init.Mode = UART_MODE_TX_RX;
	huart7.Init.HwFlowCtl = UART_HWCONTROL_RTS_CTS;
	huart7.Init.OverSampling = UART_OVERSAMPLING_16;
	huart7.Init.OneBitSampling = UART_ONE_BIT_SAMPLE_DISABLE;
	huart7.AdvancedInit.AdvFeatureInit = UART_ADVFEATURE_NO_INIT;
	if (HAL_UART_Init(&huart7) != HAL_OK)
	{
		Error_Handler();
	}

}

static void MX_USART2_UART_Init(void)
{

	huart2.Instance = USART2;
	huart2.Init.BaudRate = 115200;
	huart2.Init.WordLength = UART_WORDLENGTH_8B;
	huart2.Init.StopBits = UART_STOPBITS_1;
	huart2.Init.Parity = UART_PARITY_NONE;
	huart2.Init.Mode = UART_MODE_TX_RX;
	huart2.Init.HwFlowCtl = UART_HWCONTROL_NONE;
	huart2.Init.OverSampling = UART_OVERSAMPLING_16;
	huart2.Init.OneBitSampling = UART_ONE_BIT_SAMPLE_DISABLE;
	huart2.AdvancedInit.AdvFeatureInit = UART_ADVFEATURE_NO_INIT;
	if (HAL_UART_Init(&huart2) != HAL_OK)
	{
		Error_Handler();
	}

}

static void MX_USART6_UART_Init(void)
{

	huart6.Instance = USART6;
	huart6.Init.BaudRate = 115200;
	huart6.Init.WordLength = UART_WORDLENGTH_8B;
	huart6.Init.StopBits = UART_STOPBITS_1;
	huart6.Init.Parity = UART_PARITY_NONE;
	huart6.Init.Mode = UART_MODE_TX_RX;
	huart6.Init.HwFlowCtl = UART_HWCONTROL_NONE;
	huart6.Init.OverSampling = UART_OVERSAMPLING_16;
	huart6.Init.OneBitSampling = UART_ONE_BIT_SAMPLE_DISABLE;
	huart6.AdvancedInit.AdvFeatureInit = UART_ADVFEATURE_NO_INIT;
	if (HAL_UART_Init(&huart6) != HAL_OK)
	{
		Error_Handler();
	}

}

/* FMC initialization function */
static void MX_FMC_Init(void)
{

	FMC_NORSRAM_TimingTypeDef Timing = {0};

	/** Perform the SRAM1 memory initialization sequence
	 */
	hsram1.Instance = FMC_NORSRAM_DEVICE;
	hsram1.Extended = FMC_NORSRAM_EXTENDED_DEVICE;
	/* hsram1.Init */
	hsram1.Init.NSBank = FMC_NORSRAM_BANK1;
	hsram1.Init.DataAddressMux = FMC_DATA_ADDRESS_MUX_DISABLE;
	hsram1.Init.MemoryType = FMC_MEMORY_TYPE_PSRAM;
	hsram1.Init.MemoryDataWidth = FMC_NORSRAM_MEM_BUS_WIDTH_16;
	hsram1.Init.BurstAccessMode = FMC_BURST_ACCESS_MODE_DISABLE;
	hsram1.Init.WaitSignalPolarity = FMC_WAIT_SIGNAL_POLARITY_LOW;
	hsram1.Init.WaitSignalActive = FMC_WAIT_TIMING_BEFORE_WS;
	hsram1.Init.WriteOperation = FMC_WRITE_OPERATION_ENABLE;
	hsram1.Init.WaitSignal = FMC_WAIT_SIGNAL_DISABLE;
	hsram1.Init.ExtendedMode = FMC_EXTENDED_MODE_DISABLE;
	hsram1.Init.AsynchronousWait = FMC_ASYNCHRONOUS_WAIT_DISABLE;
	hsram1.Init.WriteBurst = FMC_WRITE_BURST_DISABLE;
	hsram1.Init.ContinuousClock = FMC_CONTINUOUS_CLOCK_SYNC_ONLY;
	hsram1.Init.WriteFifo = FMC_WRITE_FIFO_ENABLE;
	hsram1.Init.PageSize = FMC_PAGE_SIZE_NONE;
	/* Timing */
	Timing.AddressSetupTime = 15;
	Timing.AddressHoldTime = 15;
	Timing.DataSetupTime = 255;
	Timing.BusTurnAroundDuration = 15;
	Timing.CLKDivision = 16;
	Timing.DataLatency = 17;
	Timing.AccessMode = FMC_ACCESS_MODE_A;
	/* ExtTiming */

	if (HAL_SRAM_Init(&hsram1, &Timing, NULL) != HAL_OK)
	{
		Error_Handler( );
	}

	/** Perform the SRAM2 memory initialization sequence
	 */
	hsram2.Instance = FMC_NORSRAM_DEVICE;
	hsram2.Extended = FMC_NORSRAM_EXTENDED_DEVICE;
	/* hsram2.Init */
	hsram2.Init.NSBank = FMC_NORSRAM_BANK2;
	hsram2.Init.DataAddressMux = FMC_DATA_ADDRESS_MUX_DISABLE;
	hsram2.Init.MemoryType = FMC_MEMORY_TYPE_SRAM;
	hsram2.Init.MemoryDataWidth = FMC_NORSRAM_MEM_BUS_WIDTH_16;
	hsram2.Init.BurstAccessMode = FMC_BURST_ACCESS_MODE_DISABLE;
	hsram2.Init.WaitSignalPolarity = FMC_WAIT_SIGNAL_POLARITY_LOW;
	hsram2.Init.WaitSignalActive = FMC_WAIT_TIMING_BEFORE_WS;
	hsram2.Init.WriteOperation = FMC_WRITE_OPERATION_ENABLE;
	hsram2.Init.WaitSignal = FMC_WAIT_SIGNAL_DISABLE;
	hsram2.Init.ExtendedMode = FMC_EXTENDED_MODE_DISABLE;
	hsram2.Init.AsynchronousWait = FMC_ASYNCHRONOUS_WAIT_DISABLE;
	hsram2.Init.WriteBurst = FMC_WRITE_BURST_DISABLE;
	hsram2.Init.ContinuousClock = FMC_CONTINUOUS_CLOCK_SYNC_ONLY;
	hsram2.Init.WriteFifo = FMC_WRITE_FIFO_ENABLE;
	hsram2.Init.PageSize = FMC_PAGE_SIZE_NONE;
	/* Timing */
	Timing.AddressSetupTime = 15;
	Timing.AddressHoldTime = 15;
	Timing.DataSetupTime = 255;
	Timing.BusTurnAroundDuration = 15;
	Timing.CLKDivision = 16;
	Timing.DataLatency = 17;
	Timing.AccessMode = FMC_ACCESS_MODE_A;
	/* ExtTiming */

	if (HAL_SRAM_Init(&hsram2, &Timing, NULL) != HAL_OK)
	{
		Error_Handler( );
	}

}

static void MX_GPIO_Init(void)
{
	GPIO_InitTypeDef GPIO_InitStruct = {0};

	/* GPIO Ports Clock Enable */
	__HAL_RCC_GPIOE_CLK_ENABLE();
	__HAL_RCC_GPIOB_CLK_ENABLE();
	__HAL_RCC_GPIOG_CLK_ENABLE();
	__HAL_RCC_GPIOD_CLK_ENABLE();
	__HAL_RCC_GPIOC_CLK_ENABLE();
	__HAL_RCC_GPIOA_CLK_ENABLE();
	__HAL_RCC_GPIOI_CLK_ENABLE();
	__HAL_RCC_GPIOH_CLK_ENABLE();
	__HAL_RCC_GPIOF_CLK_ENABLE();

	/*Configure GPIO pin Output Level */
	HAL_GPIO_WritePin(GPIOE, ARD_D7_GPIO_Pin|ARD_D8_GPIO_Pin, GPIO_PIN_RESET);

	/*Configure GPIO pin Output Level */
	HAL_GPIO_WritePin(GPIOG, WIFI_RST_Pin|WIFI_GPIO_0_Pin|PMOD_GPIO_0_Pin|USB_OTGFS_PPWR_EN_Pin, GPIO_PIN_RESET);

	/*Configure GPIO pin Output Level */
	HAL_GPIO_WritePin(GPIOD, WIFI_GPIO_2_Pin|WIFI_CH_PD_Pin, GPIO_PIN_RESET);

	/*Configure GPIO pin Output Level */
	HAL_GPIO_WritePin(GPIOC, STMOD_UART4_RXD_s_Pin|ARD_D2_GPIO_Pin, GPIO_PIN_RESET);

	/*Configure GPIO pin Output Level */
	HAL_GPIO_WritePin(GPIOI, PMOD_SPI2_MOSI_Pin|PMOD_SPI2_MISO_Pin|GPIO_PIN_10, GPIO_PIN_RESET);

	/*Configure GPIO pin Output Level */
	HAL_GPIO_WritePin(PMOD_SEL_0_GPIO_Port, PMOD_SEL_0_Pin, GPIO_PIN_SET);

	/*Configure GPIO pin Output Level */
	HAL_GPIO_WritePin(GPIOA, USB_OTG_FS_ID_Pin|SYS_LD_USER1_Pin, GPIO_PIN_RESET);

	/*Configure GPIO pin Output Level */
	HAL_GPIO_WritePin(GPIOH, PMOD_GPIO_1_Pin|ARD_D4_GPIO_Pin|USB_OTGHS_PPWR_EN_Pin|CTP_RST_Pin
			|LCD_RST_Pin, GPIO_PIN_RESET);

	/*Configure GPIO pin Output Level */
	HAL_GPIO_WritePin(GPIOB, USB_OTG_HS_ID_Pin|SYS_LD_USER2_Pin, GPIO_PIN_RESET);

	/*Configure GPIO pins : ARD_D7_GPIO_Pin ARD_D8_GPIO_Pin */
	GPIO_InitStruct.Pin = ARD_D7_GPIO_Pin|ARD_D8_GPIO_Pin;
	GPIO_InitStruct.Mode = GPIO_MODE_OUTPUT_PP;
	GPIO_InitStruct.Pull = GPIO_NOPULL;
	GPIO_InitStruct.Speed = GPIO_SPEED_FREQ_LOW;
	HAL_GPIO_Init(GPIOE, &GPIO_InitStruct);

	/*Configure GPIO pin : QSPI_D2_Pin */
	GPIO_InitStruct.Pin = QSPI_D2_Pin;
	GPIO_InitStruct.Mode = GPIO_MODE_AF_PP;
	GPIO_InitStruct.Pull = GPIO_NOPULL;
	GPIO_InitStruct.Speed = GPIO_SPEED_FREQ_VERY_HIGH;
	GPIO_InitStruct.Alternate = GPIO_AF9_QUADSPI;
	HAL_GPIO_Init(QSPI_D2_GPIO_Port, &GPIO_InitStruct);

	/*Configure GPIO pins : LSM6DSM_INT1_Pin USB_OTG_HS_VBUS_Pin JP10_Pin USB_OTGFS_OVCR_INT_Pin
                           PMOD_INT_Pin */
	GPIO_InitStruct.Pin = LSM6DSM_INT1_Pin|USB_OTG_HS_VBUS_Pin|JP10_Pin|USB_OTGFS_OVCR_INT_Pin
			|PMOD_INT_Pin;
	GPIO_InitStruct.Mode = GPIO_MODE_IT_RISING;
	GPIO_InitStruct.Pull = GPIO_NOPULL;
	HAL_GPIO_Init(GPIOB, &GPIO_InitStruct);

	/*Configure GPIO pins : WIFI_RST_Pin WIFI_GPIO_0_Pin PMOD_GPIO_0_Pin USB_OTGFS_PPWR_EN_Pin */
	GPIO_InitStruct.Pin = WIFI_RST_Pin|WIFI_GPIO_0_Pin|PMOD_GPIO_0_Pin|USB_OTGFS_PPWR_EN_Pin;
	GPIO_InitStruct.Mode = GPIO_MODE_OUTPUT_PP;
	GPIO_InitStruct.Pull = GPIO_NOPULL;
	GPIO_InitStruct.Speed = GPIO_SPEED_FREQ_LOW;
	HAL_GPIO_Init(GPIOG, &GPIO_InitStruct);

	/*Configure GPIO pin : LSM6DSM_INT2_Pin */
	GPIO_InitStruct.Pin = LSM6DSM_INT2_Pin;
	GPIO_InitStruct.Mode = GPIO_MODE_INPUT;
	GPIO_InitStruct.Pull = GPIO_NOPULL;
	HAL_GPIO_Init(LSM6DSM_INT2_GPIO_Port, &GPIO_InitStruct);

	/*Configure GPIO pin : QSPI_NCS_Pin */
	GPIO_InitStruct.Pin = QSPI_NCS_Pin;
	GPIO_InitStruct.Mode = GPIO_MODE_AF_PP;
	GPIO_InitStruct.Pull = GPIO_NOPULL;
	GPIO_InitStruct.Speed = GPIO_SPEED_FREQ_VERY_HIGH;
	GPIO_InitStruct.Alternate = GPIO_AF10_QUADSPI;
	HAL_GPIO_Init(QSPI_NCS_GPIO_Port, &GPIO_InitStruct);

	/*Configure GPIO pin : SAI2_INT_Pin */
	GPIO_InitStruct.Pin = SAI2_INT_Pin;
	GPIO_InitStruct.Mode = GPIO_MODE_IT_RISING;
	GPIO_InitStruct.Pull = GPIO_NOPULL;
	HAL_GPIO_Init(SAI2_INT_GPIO_Port, &GPIO_InitStruct);

	/*Configure GPIO pin : SAI2_SD_B_Pin */
	GPIO_InitStruct.Pin = SAI2_SD_B_Pin;
	GPIO_InitStruct.Mode = GPIO_MODE_AF_PP;
	GPIO_InitStruct.Pull = GPIO_NOPULL;
	GPIO_InitStruct.Speed = GPIO_SPEED_FREQ_LOW;
	GPIO_InitStruct.Alternate = GPIO_AF10_SAI2;
	HAL_GPIO_Init(SAI2_SD_B_GPIO_Port, &GPIO_InitStruct);

	/*Configure GPIO pins : WIFI_GPIO_2_Pin WIFI_CH_PD_Pin */
	GPIO_InitStruct.Pin = WIFI_GPIO_2_Pin|WIFI_CH_PD_Pin;
	GPIO_InitStruct.Mode = GPIO_MODE_OUTPUT_PP;
	GPIO_InitStruct.Pull = GPIO_NOPULL;
	GPIO_InitStruct.Speed = GPIO_SPEED_FREQ_LOW;
	HAL_GPIO_Init(GPIOD, &GPIO_InitStruct);

	/*Configure GPIO pins : STMOD_UART4_RXD_s_Pin ARD_D2_GPIO_Pin */
	GPIO_InitStruct.Pin = STMOD_UART4_RXD_s_Pin|ARD_D2_GPIO_Pin;
	GPIO_InitStruct.Mode = GPIO_MODE_OUTPUT_PP;
	GPIO_InitStruct.Pull = GPIO_NOPULL;
	GPIO_InitStruct.Speed = GPIO_SPEED_FREQ_LOW;
	HAL_GPIO_Init(GPIOC, &GPIO_InitStruct);

	/*Configure GPIO pins : QSPI_D1_Pin QSPI_D0_Pin */
	GPIO_InitStruct.Pin = QSPI_D1_Pin|QSPI_D0_Pin;
	GPIO_InitStruct.Mode = GPIO_MODE_AF_PP;
	GPIO_InitStruct.Pull = GPIO_NOPULL;
	GPIO_InitStruct.Speed = GPIO_SPEED_FREQ_VERY_HIGH;
	GPIO_InitStruct.Alternate = GPIO_AF9_QUADSPI;
	HAL_GPIO_Init(GPIOC, &GPIO_InitStruct);

	/*Configure GPIO pins : PA12 PA11 */
	GPIO_InitStruct.Pin = GPIO_PIN_12|GPIO_PIN_11;
	GPIO_InitStruct.Mode = GPIO_MODE_AF_PP;
	GPIO_InitStruct.Pull = GPIO_NOPULL;
	GPIO_InitStruct.Speed = GPIO_SPEED_FREQ_VERY_HIGH;
	GPIO_InitStruct.Alternate = GPIO_AF10_OTG_FS;
	HAL_GPIO_Init(GPIOA, &GPIO_InitStruct);

	/*Configure GPIO pins : SAI2_FS_A_Pin SAI2_SD_A_Pin SAI2_SCK_A_Pin SAI2_MCLK_A_Pin */
	GPIO_InitStruct.Pin = SAI2_FS_A_Pin|SAI2_SD_A_Pin|SAI2_SCK_A_Pin|SAI2_MCLK_A_Pin;
	GPIO_InitStruct.Mode = GPIO_MODE_AF_PP;
	GPIO_InitStruct.Pull = GPIO_NOPULL;
	GPIO_InitStruct.Speed = GPIO_SPEED_FREQ_LOW;
	GPIO_InitStruct.Alternate = GPIO_AF10_SAI2;
	HAL_GPIO_Init(GPIOI, &GPIO_InitStruct);

	/*Configure GPIO pins : PMOD_SPI2_MOSI_Pin PMOD_SPI2_MISO_Pin PI10 */
	GPIO_InitStruct.Pin = PMOD_SPI2_MOSI_Pin|PMOD_SPI2_MISO_Pin|GPIO_PIN_10;
	GPIO_InitStruct.Mode = GPIO_MODE_OUTPUT_PP;
	GPIO_InitStruct.Pull = GPIO_NOPULL;
	GPIO_InitStruct.Speed = GPIO_SPEED_FREQ_LOW;
	HAL_GPIO_Init(GPIOI, &GPIO_InitStruct);

	/*Configure GPIO pin : CTP_INT_Pin */
	GPIO_InitStruct.Pin = CTP_INT_Pin;
	GPIO_InitStruct.Mode = GPIO_MODE_IT_RISING;
	GPIO_InitStruct.Pull = GPIO_NOPULL;
	HAL_GPIO_Init(CTP_INT_GPIO_Port, &GPIO_InitStruct);

	/*Configure GPIO pins : PMOD_SEL_0_Pin PMOD_GPIO_1_Pin ARD_D4_GPIO_Pin USB_OTGHS_PPWR_EN_Pin
                           CTP_RST_Pin LCD_RST_Pin */
	GPIO_InitStruct.Pin = PMOD_SEL_0_Pin|PMOD_GPIO_1_Pin|ARD_D4_GPIO_Pin|USB_OTGHS_PPWR_EN_Pin
			|CTP_RST_Pin|LCD_RST_Pin;
	GPIO_InitStruct.Mode = GPIO_MODE_OUTPUT_PP;
	GPIO_InitStruct.Pull = GPIO_NOPULL;
	GPIO_InitStruct.Speed = GPIO_SPEED_FREQ_LOW;
	HAL_GPIO_Init(GPIOH, &GPIO_InitStruct);

	/*Configure GPIO pins : PMOD_SPI2_SCK_Pin PMOD_SPI2_NSS_Pin */
	GPIO_InitStruct.Pin = PMOD_SPI2_SCK_Pin|PMOD_SPI2_NSS_Pin;
	GPIO_InitStruct.Mode = GPIO_MODE_AF_PP;
	GPIO_InitStruct.Pull = GPIO_NOPULL;
	GPIO_InitStruct.Speed = GPIO_SPEED_FREQ_VERY_HIGH;
	GPIO_InitStruct.Alternate = GPIO_AF5_SPI2;
	HAL_GPIO_Init(GPIOI, &GPIO_InitStruct);

	/*Configure GPIO pins : USB_OTG_FS_ID_Pin SYS_LD_USER1_Pin */
	GPIO_InitStruct.Pin = USB_OTG_FS_ID_Pin|SYS_LD_USER1_Pin;
	GPIO_InitStruct.Mode = GPIO_MODE_OUTPUT_PP;
	GPIO_InitStruct.Pull = GPIO_NOPULL;
	GPIO_InitStruct.Speed = GPIO_SPEED_FREQ_LOW;
	HAL_GPIO_Init(GPIOA, &GPIO_InitStruct);

	/*Configure GPIO pin : PA9 */
	GPIO_InitStruct.Pin = GPIO_PIN_9;
	GPIO_InitStruct.Mode = GPIO_MODE_INPUT;
	GPIO_InitStruct.Pull = GPIO_NOPULL;
	HAL_GPIO_Init(GPIOA, &GPIO_InitStruct);

	/*Configure GPIO pin : CTP_SCL_Pin */
	GPIO_InitStruct.Pin = CTP_SCL_Pin;
	GPIO_InitStruct.Mode = GPIO_MODE_AF_OD;
	GPIO_InitStruct.Pull = GPIO_NOPULL;
	GPIO_InitStruct.Speed = GPIO_SPEED_FREQ_VERY_HIGH;
	GPIO_InitStruct.Alternate = GPIO_AF4_I2C3;
	HAL_GPIO_Init(CTP_SCL_GPIO_Port, &GPIO_InitStruct);

	/*Configure GPIO pin : LCD_TE_INT_Pin */
	GPIO_InitStruct.Pin = LCD_TE_INT_Pin;
	GPIO_InitStruct.Mode = GPIO_MODE_IT_RISING;
	GPIO_InitStruct.Pull = GPIO_NOPULL;
	HAL_GPIO_Init(LCD_TE_INT_GPIO_Port, &GPIO_InitStruct);

	/*Configure GPIO pin : ARD_A3_ADC3_IN8_Pin */
	GPIO_InitStruct.Pin = ARD_A3_ADC3_IN8_Pin;
	GPIO_InitStruct.Mode = GPIO_MODE_ANALOG;
	GPIO_InitStruct.Pull = GPIO_NOPULL;
	HAL_GPIO_Init(ARD_A3_ADC3_IN8_GPIO_Port, &GPIO_InitStruct);

	/*Configure GPIO pin : LCD_BL_Pin */
	GPIO_InitStruct.Pin = LCD_BL_Pin;
	GPIO_InitStruct.Mode = GPIO_MODE_AF_PP;
	GPIO_InitStruct.Pull = GPIO_NOPULL;
	GPIO_InitStruct.Speed = GPIO_SPEED_FREQ_LOW;
	GPIO_InitStruct.Alternate = GPIO_AF2_TIM5;
	HAL_GPIO_Init(LCD_BL_GPIO_Port, &GPIO_InitStruct);

	/*Configure GPIO pin : USB_OTGHS_OVCR_INT_Pin */
	GPIO_InitStruct.Pin = USB_OTGHS_OVCR_INT_Pin;
	GPIO_InitStruct.Mode = GPIO_MODE_INPUT;
	GPIO_InitStruct.Pull = GPIO_NOPULL;
	HAL_GPIO_Init(USB_OTGHS_OVCR_INT_GPIO_Port, &GPIO_InitStruct);

	/*Configure GPIO pins : M_INT1_Pin M_INT2_Pin */
	GPIO_InitStruct.Pin = M_INT1_Pin|M_INT2_Pin;
	GPIO_InitStruct.Mode = GPIO_MODE_INPUT;
	GPIO_InitStruct.Pull = GPIO_NOPULL;
	HAL_GPIO_Init(GPIOC, &GPIO_InitStruct);

	/*Configure GPIO pins : STMOD_SPI2_MISOs_Pin STMOD__SPI2_MOSIs_Pin */
	GPIO_InitStruct.Pin = STMOD_SPI2_MISOs_Pin|STMOD__SPI2_MOSIs_Pin;
	GPIO_InitStruct.Mode = GPIO_MODE_AF_PP;
	GPIO_InitStruct.Pull = GPIO_NOPULL;
	GPIO_InitStruct.Speed = GPIO_SPEED_FREQ_VERY_HIGH;
	GPIO_InitStruct.Alternate = GPIO_AF5_SPI2;
	HAL_GPIO_Init(GPIOC, &GPIO_InitStruct);

	/*Configure GPIO pin : QSPI_CLK_Pin */
	GPIO_InitStruct.Pin = QSPI_CLK_Pin;
	GPIO_InitStruct.Mode = GPIO_MODE_AF_PP;
	GPIO_InitStruct.Pull = GPIO_NOPULL;
	GPIO_InitStruct.Speed = GPIO_SPEED_FREQ_VERY_HIGH;
	GPIO_InitStruct.Alternate = GPIO_AF9_QUADSPI;
	HAL_GPIO_Init(QSPI_CLK_GPIO_Port, &GPIO_InitStruct);

	/*Configure GPIO pin : ARD_D9_TIM12_CH1_Pin */
	GPIO_InitStruct.Pin = ARD_D9_TIM12_CH1_Pin;
	GPIO_InitStruct.Mode = GPIO_MODE_AF_PP;
	GPIO_InitStruct.Pull = GPIO_NOPULL;
	GPIO_InitStruct.Speed = GPIO_SPEED_FREQ_LOW;
	GPIO_InitStruct.Alternate = GPIO_AF9_TIM12;
	HAL_GPIO_Init(ARD_D9_TIM12_CH1_GPIO_Port, &GPIO_InitStruct);

	/*Configure GPIO pin : CTP_SDA_Pin */
	GPIO_InitStruct.Pin = CTP_SDA_Pin;
	GPIO_InitStruct.Mode = GPIO_MODE_AF_OD;
	GPIO_InitStruct.Pull = GPIO_NOPULL;
	GPIO_InitStruct.Speed = GPIO_SPEED_FREQ_VERY_HIGH;
	GPIO_InitStruct.Alternate = GPIO_AF4_I2C3;
	HAL_GPIO_Init(CTP_SDA_GPIO_Port, &GPIO_InitStruct);

	/*Configure GPIO pin : QSPI_D3_Pin */
	GPIO_InitStruct.Pin = QSPI_D3_Pin;
	GPIO_InitStruct.Mode = GPIO_MODE_AF_PP;
	GPIO_InitStruct.Pull = GPIO_NOPULL;
	GPIO_InitStruct.Speed = GPIO_SPEED_FREQ_VERY_HIGH;
	GPIO_InitStruct.Alternate = GPIO_AF9_QUADSPI;
	HAL_GPIO_Init(QSPI_D3_GPIO_Port, &GPIO_InitStruct);

	/*Configure GPIO pin : JP9_Pin */
	GPIO_InitStruct.Pin = JP9_Pin;
	GPIO_InitStruct.Mode = GPIO_MODE_IT_RISING;
	GPIO_InitStruct.Pull = GPIO_NOPULL;
	HAL_GPIO_Init(JP9_GPIO_Port, &GPIO_InitStruct);

	/*Configure GPIO pin : ARD_A2_Pin */
	GPIO_InitStruct.Pin = ARD_A2_Pin;
	GPIO_InitStruct.Mode = GPIO_MODE_ANALOG;
	GPIO_InitStruct.Pull = GPIO_NOPULL;
	HAL_GPIO_Init(GPIOC, &GPIO_InitStruct);

	/*Configure GPIO pin : ARD_A0_Pin */
	GPIO_InitStruct.Pin = ARD_A0_Pin;
	GPIO_InitStruct.Mode = GPIO_MODE_ANALOG;
	GPIO_InitStruct.Pull = GPIO_NOPULL;
	HAL_GPIO_Init(GPIOA, &GPIO_InitStruct);

	/*Configure GPIO pin : ARD_D13_SPI1_SCK_Pin */
	GPIO_InitStruct.Pin = ARD_D13_SPI1_SCK_Pin;
	GPIO_InitStruct.Mode = GPIO_MODE_AF_PP;
	GPIO_InitStruct.Pull = GPIO_NOPULL;
	GPIO_InitStruct.Speed = GPIO_SPEED_FREQ_VERY_HIGH;
	GPIO_InitStruct.Alternate = GPIO_AF5_SPI1;
	HAL_GPIO_Init(ARD_D13_SPI1_SCK_GPIO_Port, &GPIO_InitStruct);

	/*Configure GPIO pins : USB_OTG_HS_ID_Pin SYS_LD_USER2_Pin */
	GPIO_InitStruct.Pin = USB_OTG_HS_ID_Pin|SYS_LD_USER2_Pin;
	GPIO_InitStruct.Mode = GPIO_MODE_OUTPUT_PP;
	GPIO_InitStruct.Pull = GPIO_NOPULL;
	GPIO_InitStruct.Speed = GPIO_SPEED_FREQ_LOW;
	HAL_GPIO_Init(GPIOB, &GPIO_InitStruct);

	/*Configure GPIO pin : PMOD_RESET_Pin */
	GPIO_InitStruct.Pin = PMOD_RESET_Pin;
	GPIO_InitStruct.Mode = GPIO_MODE_INPUT;
	GPIO_InitStruct.Pull = GPIO_NOPULL;
	HAL_GPIO_Init(PMOD_RESET_GPIO_Port, &GPIO_InitStruct);

	/*Configure GPIO pins : PB14 PB15 */
	GPIO_InitStruct.Pin = GPIO_PIN_14|GPIO_PIN_15;
	GPIO_InitStruct.Mode = GPIO_MODE_AF_PP;
	GPIO_InitStruct.Pull = GPIO_NOPULL;
	GPIO_InitStruct.Speed = GPIO_SPEED_FREQ_VERY_HIGH;
	GPIO_InitStruct.Alternate = GPIO_AF12_OTG_HS_FS;
	HAL_GPIO_Init(GPIOB, &GPIO_InitStruct);

}

/* USER CODE BEGIN 4 */

void HAL_TIM_IC_CaptureCallback(TIM_HandleTypeDef *htim)
{
	if (htim->Channel == HAL_TIM_ACTIVE_CHANNEL_1)
	{
		if(uhCaptureIndex == 0)
		{
			/* Get the 1st Input Capture value */
			captures[0] = HAL_TIM_ReadCapturedValue(htim, TIM_CHANNEL_1);
			uhCaptureIndex = 1;
		}
		else if(uhCaptureIndex == 1)
		{
			/* Get the 2nd Input Capture value */
			captures[1] = HAL_TIM_ReadCapturedValue(htim, TIM_CHANNEL_1);
			/* Capture computation */
			if (captures[1] >= captures[0])
				diffCapture = captures[1] - captures[0];
			else
				diffCapture = ((htim->Instance->ARR - captures[0]) + captures[1]) + 1;

			uhCaptureIndex = 0;
			captureDone=1;
		}
	}
}

static float getFrequency(){
	captureDone=0;

	while(!captureDone) {}
	/* Frequency computation: for this example TIMx (TIM2) is clocked by APB1Clk */
	float frequency = 2.0*HAL_RCC_GetPCLK1Freq()/ (htim2.Instance->PSC + 1.0);
	frequency = frequency / (float) diffCapture;
	return frequency;
}

/* USER CODE END 4 */

void Error_Handler(void)
{
	/* USER CODE BEGIN Error_Handler_Debug */
	/* User can add his own implementation to report the HAL error return state */
	 while(1) {
		 HAL_GPIO_TogglePin(GPIOA, GPIO_PIN_7);
		 /* Insert delay 500 ms */
		 HAL_Delay(500);
	 }
	/* USER CODE END Error_Handler_Debug */
}

/************************ (C) COPYRIGHT STMicroelectronics *****END OF FILE****/
